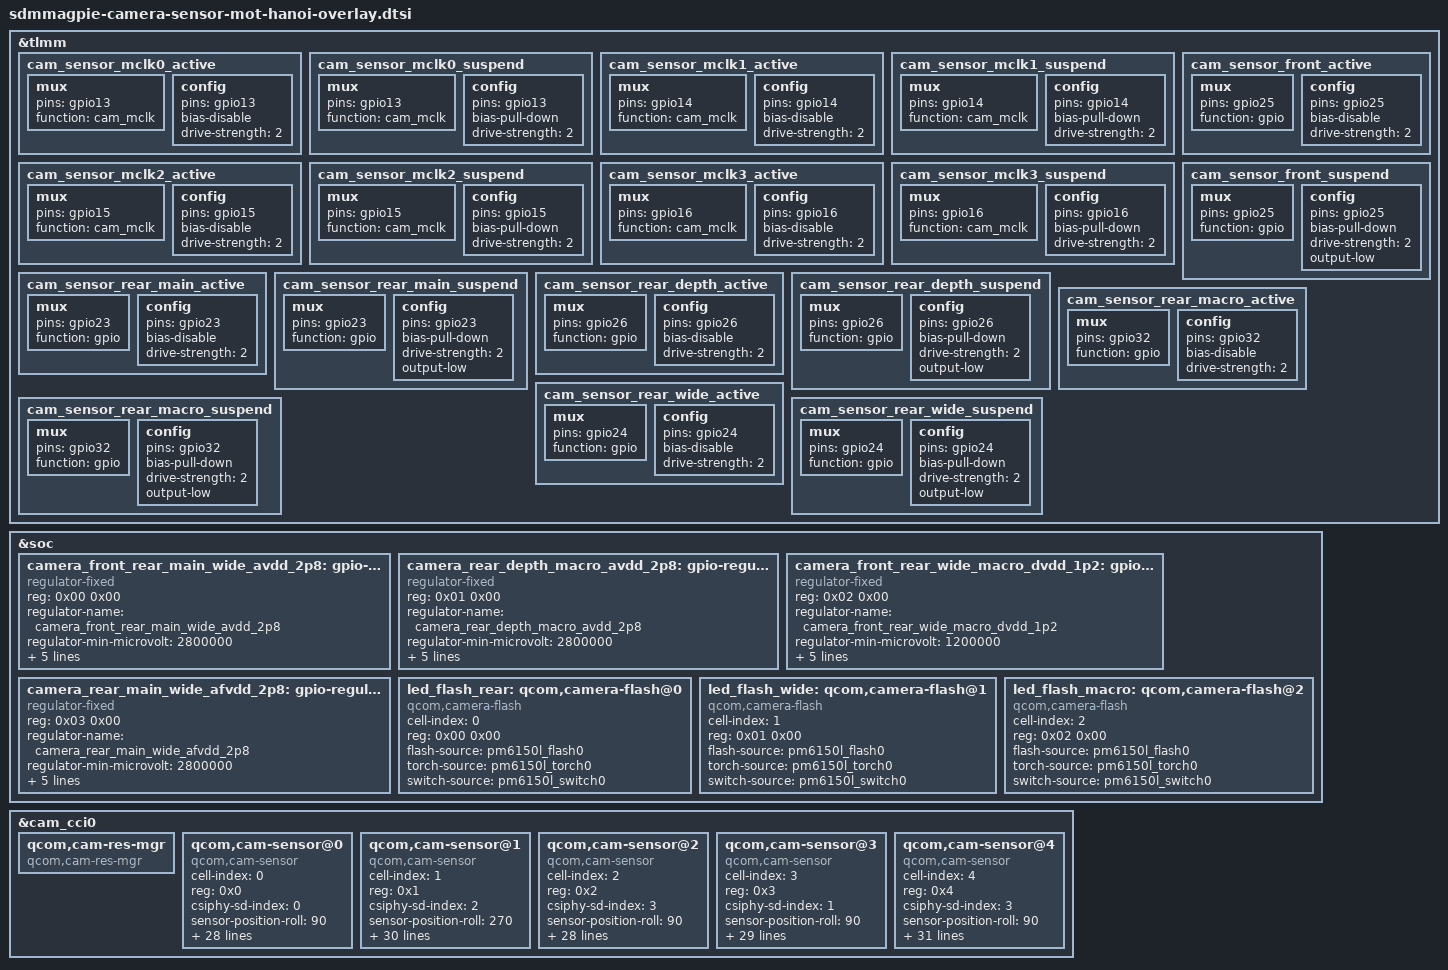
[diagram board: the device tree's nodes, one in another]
/*
 * Copyright (c) 2018-2019, The Linux Foundation. All rights reserved.
 *
 * This program is free software; you can redistribute it and/or modify
 * it under the terms of the GNU General Public License version 2 and
 * only version 2 as published by the Free Software Foundation.
 *
 * This program is distributed in the hope that it will be useful,
 * but WITHOUT ANY WARRANTY; without even the implied warranty of
 * MERCHANTABILITY or FITNESS FOR A PARTICULAR PURPOSE.  See the
 * GNU General Public License for more details.
 */
&tlmm {
/*MCLKs*/
	cam_sensor_mclk0_active: cam_sensor_mclk0_active {
		/* MCLK0 */
		mux {
			pins = "gpio13";
			function = "cam_mclk";
		};

		config {
			pins = "gpio13";
			bias-disable; /* No PULL */
			drive-strength = <2>; /* 2 MA */
		};
	};

	cam_sensor_mclk0_suspend: cam_sensor_mclk0_suspend {
		/* MCLK0 */
		mux {
			pins = "gpio13";
			function = "cam_mclk";
		};

		config {
			pins = "gpio13";
			bias-pull-down; /* PULL DOWN */
			drive-strength = <2>; /* 2 MA */
		};
	};

	cam_sensor_mclk1_active: cam_sensor_mclk1_active {
		/* MCLK1 */
		mux {
			pins = "gpio14";
			function = "cam_mclk";
		};

		config {
			pins = "gpio14";
			bias-disable; /* No PULL */
			drive-strength = <2>; /* 2 MA */
		};
	};

	cam_sensor_mclk1_suspend: cam_sensor_mclk1_suspend {
		/* MCLK1 */
		mux {
			pins = "gpio14";
			function = "cam_mclk";
		};

		config {
			pins = "gpio14";
			bias-pull-down; /* PULL DOWN */
			drive-strength = <2>; /* 2 MA */
		};
	};

	cam_sensor_mclk2_active: cam_sensor_mclk2_active {
		/* MCLK2 */
		mux {
			pins = "gpio15";
			function = "cam_mclk";
		};

		config {
			pins = "gpio15";
			bias-disable; /* No PULL */
			drive-strength = <2>; /* 2 MA */
		};
	};

	cam_sensor_mclk2_suspend: cam_sensor_mclk2_suspend {
		/* MCLK2 */
		mux {
			pins = "gpio15";
			function = "cam_mclk";
		};

		config {
			pins = "gpio15";
			bias-pull-down; /* PULL DOWN */
			drive-strength = <2>; /* 2 MA */
		};
	};

	cam_sensor_mclk3_active: cam_sensor_mclk3_active {
		/* MCLK3 */
		mux {
			pins = "gpio16";
			function = "cam_mclk";
		};

		config {
			pins = "gpio16";
			bias-disable; /* No PULL */
			drive-strength = <2>; /* 2 MA */
		};
	};

	cam_sensor_mclk3_suspend: cam_sensor_mclk3_suspend {
		/* MCLK3 */
		mux {
			pins = "gpio16";
			function = "cam_mclk";
		};

		config {
			pins = "gpio16";
			bias-pull-down; /* PULL DOWN */
			drive-strength = <2>; /* 2 MA */
		};
	};
/*RESETs*/
	cam_sensor_front_active: cam_sensor_front_active {
		/* CAM2_RST  */
		mux {
			pins = "gpio25";
			function = "gpio";
		};

		config {
			pins = "gpio25";
			bias-disable; /* No PULL */
			drive-strength = <2>; /* 2 MA */
		};
	};

	cam_sensor_front_suspend: cam_sensor_front_suspend {
		/* CAM2_RST */
		mux {
			pins = "gpio25";
			function = "gpio";
		};

		config {
			pins = "gpio25";
			bias-pull-down; /* PULL DOWN */
			drive-strength = <2>; /* 2 MA */
			output-low;
		};
	};

	cam_sensor_rear_main_active: cam_sensor_rear_main_active {
		/* CAM0_RST  */
		mux {
			pins = "gpio23";
			function = "gpio";
		};

		config {
			pins = "gpio23";
			bias-disable; /* No PULL */
			drive-strength = <2>; /* 2 MA */
		};
	};

	cam_sensor_rear_main_suspend: cam_sensor_rear_main_suspend {
		/* CAM0_RST */
		mux {
			pins = "gpio23";
			function = "gpio";
		};

		config {
			pins = "gpio23";
			bias-pull-down; /* PULL DOWN */
			drive-strength = <2>; /* 2 MA */
			output-low;
		};
	};

	cam_sensor_rear_depth_active: cam_sensor_rear_depth_active {
		/* CAM3_RST  */
		mux {
			pins = "gpio26";
			function = "gpio";
		};

		config {
			pins = "gpio26";
			bias-disable; /* No PULL */
			drive-strength = <2>; /* 2 MA */
		};
	};

	cam_sensor_rear_depth_suspend: cam_sensor_rear_depth_suspend {
		/* CAM3_RST */
		mux {
			pins = "gpio26";
			function = "gpio";
		};

		config {
			pins = "gpio26";
			bias-pull-down; /* PULL DOWN */
			drive-strength = <2>; /* 2 MA */
			output-low;
		};
	};

	cam_sensor_rear_macro_active: cam_sensor_rear_macro_active {
		/* CAM4_RST  */
		mux {
			pins = "gpio32";
			function = "gpio";
		};

		config {
			pins = "gpio32";
			bias-disable; /* No PULL */
			drive-strength = <2>; /* 2 MA */
		};
	};

	cam_sensor_rear_macro_suspend: cam_sensor_rear_macro_suspend {
		/* CAM4_RST */
		mux {
			pins = "gpio32";
			function = "gpio";
		};

		config {
			pins = "gpio32";
			bias-pull-down; /* PULL DOWN */
			drive-strength = <2>; /* 2 MA */
			output-low;
		};
	};

	cam_sensor_rear_wide_active: cam_sensor_rear_wide_active {
		/* CAM1_RST  */
		mux {
			pins = "gpio24";
			function = "gpio";
		};

		config {
			pins = "gpio24";
			bias-disable; /* No PULL */
			drive-strength = <2>; /* 2 MA */
		};
	};

	cam_sensor_rear_wide_suspend: cam_sensor_rear_wide_suspend {
		/* CAM1_RST */
		mux {
			pins = "gpio24";
			function = "gpio";
		};

		config {
			pins = "gpio24";
			bias-pull-down; /* PULL DOWN */
			drive-strength = <2>; /* 2 MA */
			output-low;
		};
	};
};

&soc {
/*regulators*/
	camera_front_rear_main_wide_avdd_2p8: gpio-regulator@0 {
		/* REAR_CAM_AVDD_2P8*/
		compatible = "regulator-fixed";
		reg = <0x00 0x00>;
		regulator-name = "camera_front_rear_main_wide_avdd_2p8";
		regulator-min-microvolt = <2800000>;
		regulator-max-microvolt = <2800000>;
		regulator-enable-ramp-delay = <233>;
		enable-active-high;
		gpio = <&tlmm 65 0>; /* CAM_R_AVDD_EN*/
		vin-supply = <&pm6150l_bob>; /* VREG_BOB*/
	};

	camera_rear_depth_macro_avdd_2p8: gpio-regulator@1 {
		/* SLAVE_CAM_AVDD_2P8*/
		compatible = "regulator-fixed";
		reg = <0x01 0x00>;
		regulator-name = "camera_rear_depth_macro_avdd_2p8";
		regulator-min-microvolt = <2800000>;
		regulator-max-microvolt = <2800000>;
		regulator-enable-ramp-delay = <233>;
		enable-active-high;
		gpio = <&tlmm 46 0>; /* CAM_S_AVDD_EN*/
		vin-supply = <&pm6150l_bob>; /* VREG_BOB*/
	};

	camera_front_rear_wide_macro_dvdd_1p2: gpio-regulator@2 {
		/* CAM_1P2_DVDD*/
		compatible = "regulator-fixed";
		reg = <0x02 0x00>;
		regulator-name = "camera_front_rear_wide_macro_dvdd_1p2";
		regulator-min-microvolt = <1200000>;
		regulator-max-microvolt = <1200000>;
		regulator-enable-ramp-delay = <233>;
		enable-active-high;
		gpio = <&tlmm 33 0>; /* CAM_S_DVDD_EN*/
		vin-supply = <&pm6150l_s8>; /* VREG_S8C_1P35*/ /*bias: VREG_BOB*/
	};

	camera_rear_main_wide_afvdd_2p8: gpio-regulator@3 {
		/*CAM_AFVCC_2P8*/
		compatible = "regulator-fixed";
		reg = <0x03 0x00>;
		regulator-name = "camera_rear_main_wide_afvdd_2p8";
		regulator-min-microvolt = <2800000>;
		regulator-max-microvolt = <2800000>;
		regulator-enable-ramp-delay = <233>;
		enable-active-high;
		gpio = <&tlmm 64 0>; /* CAM_R_AFVDD_EN*/
		vin-supply = <&pm6150l_bob>; /*VREG_BOB*/
	};

	led_flash_rear: qcom,camera-flash@0 {
		cell-index = <0>;
		reg = <0x00 0x00>;
		compatible = "qcom,camera-flash";
		flash-source = <&pm6150l_flash0>;
		torch-source = <&pm6150l_torch0>;
		switch-source = <&pm6150l_switch0>;
		status = "ok";
	};

	led_flash_wide: qcom,camera-flash@1 {
		cell-index = <1>;
		reg = <0x01 0x00>;
		compatible = "qcom,camera-flash";
		flash-source = <&pm6150l_flash0>;
		torch-source = <&pm6150l_torch0>;
		switch-source = <&pm6150l_switch0>;
		status = "ok";
	};


	led_flash_macro: qcom,camera-flash@2 {
		cell-index = <2>;
		reg = <0x02 0x00>;
		compatible = "qcom,camera-flash";
		flash-source = <&pm6150l_flash0>;
		torch-source = <&pm6150l_torch0>;
		switch-source = <&pm6150l_switch0>;
		status = "ok";
	};

};

&cam_cci0 {
	qcom,cam-res-mgr {
		compatible = "qcom,cam-res-mgr";
		status = "ok";
	};

	qcom,cam-sensor@0 {
		/*rear main ov64b*/
		cell-index = <0>;
		compatible = "qcom,cam-sensor";
		reg = <0x0>;
		csiphy-sd-index = <0>;
		sensor-position-roll = <90>;
		sensor-position-pitch = <0>;
		sensor-position-yaw = <180>;
		cam_vio-supply = <&pm6150_l13>;
		cam_vana-supply = <&camera_front_rear_main_wide_avdd_2p8>;
		cam_vdig-supply = <&pm6150_l6>;
		cam_clk-supply = <&titan_top_gdsc>;
		regulator-names = "cam_vio", "cam_vana", "cam_vdig", "cam_clk";
		rgltr-cntrl-support;
		rgltr-min-voltage = <1800000 2800000 1100000 0>;
		rgltr-max-voltage = <1800000 2800000 1100000 0>;
		rgltr-load-current = <0 80000 105000 0>;
		gpio-no-mux = <0>;
		pinctrl-names = "cam_default", "cam_suspend";
		pinctrl-0 = <&cam_sensor_mclk0_active
				&cam_sensor_rear_main_active>;
		pinctrl-1 = <&cam_sensor_mclk0_suspend
				&cam_sensor_rear_main_suspend>;
		gpios = <&tlmm 13 0>,
			<&tlmm 23 0>;
		gpio-reset = <1>;
		gpio-req-tbl-num = <0 1>;
		gpio-req-tbl-flags = <1 0>;
		gpio-req-tbl-label = "CAMIF_MCLK0", "CAM_RESET0";
		cci-device = <0>;
		cci-master = <0>;
		status = "ok";
		clocks = <&clock_camcc CAM_CC_MCLK0_CLK>;
		clock-names = "cam_clk";
		clock-cntl-level = "turbo";
		clock-rates = <24000000>;
	};

	qcom,cam-sensor@1 {
		/*front ov16a1q*/
		cell-index = <1>;
		compatible = "qcom,cam-sensor";
		reg = <0x1>;
		csiphy-sd-index = <2>;
		sensor-position-roll = <270>;
		sensor-position-pitch = <0>;
		sensor-position-yaw = <0>;
		cam_vio-supply = <&pm6150_l13>;
		cam_vana-supply = <&camera_front_rear_main_wide_avdd_2p8>;
		cam_vdig-supply = <&camera_front_rear_wide_macro_dvdd_1p2>;
		cam_clk-supply = <&titan_top_gdsc>;
		regulator-names = "cam_vio", "cam_vana", "cam_vdig", "cam_clk";
		rgltr-cntrl-support;
		rgltr-min-voltage = <1800000 2800000 1200000 0>;
		rgltr-max-voltage = <1800000 2800000 1200000 0>;
		rgltr-load-current = <0 80000 105000 0>;
		gpio-no-mux = <0>;
		pinctrl-names = "cam_default", "cam_suspend";
		pinctrl-0 = <&cam_sensor_mclk2_active
				&cam_sensor_front_active>;
		pinctrl-1 = <&cam_sensor_mclk2_suspend
				&cam_sensor_front_suspend>;
		gpios = <&tlmm 15 0>,
			<&tlmm 25 0>;
		gpio-reset = <1>;
		gpio-req-tbl-num = <0 1>;
		gpio-req-tbl-flags = <1 0>;
		gpio-req-tbl-label = "CAMIF_MCLK2", "CAM_RESET2";
		sensor-mode = <1>;
		cci-device = <0>;
		cci-master = <0>;
		status = "ok";
		clocks = <&clock_camcc CAM_CC_MCLK2_CLK>;
		clock-names = "cam_clk";
		clock-cntl-level = "turbo";
		clock-rates = <24000000>;
	};

	qcom,cam-sensor@2 {
		/*rear depth ov02b1b*/
		cell-index = <2>;
		compatible = "qcom,cam-sensor";
		reg = <0x2>;
		csiphy-sd-index = <3>;
		sensor-position-roll = <90>;
		sensor-position-pitch = <0>;
		sensor-position-yaw = <180>;
		cam_vio-supply = <&pm6150_l13>;
		cam_vana-supply = <&camera_rear_depth_macro_avdd_2p8>;
		cam_clk-supply = <&titan_top_gdsc>;
		regulator-names = "cam_vio", "cam_vana", "cam_clk";
		rgltr-cntrl-support;
		rgltr-min-voltage = <1800000 2800000 0>;
		rgltr-max-voltage = <1800000 2800000 0>;
		rgltr-load-current = <0 80000 0>;
		gpio-no-mux = <0>;
		pinctrl-names = "cam_default", "cam_suspend";
		pinctrl-0 = <&cam_sensor_mclk3_active
				&cam_sensor_rear_depth_active>;
		pinctrl-1 = <&cam_sensor_mclk3_suspend
				&cam_sensor_rear_depth_suspend>;
		gpios = <&tlmm 16 0>,
			<&tlmm 26 0>,
			<&tlmm 42 0>; /*MIPI_SEL=0 for depth*/
		gpio-reset = <1>;
		gpio-custom1 = <2>;
		gpio-req-tbl-num = <0 1 2>;
		gpio-req-tbl-flags = <1 0 0>;
		gpio-req-tbl-label = "CAMIF_MCLK3", "CAM_RESET3", "CAM_MIPI_SEL";
		cci-device = <0>;
		cci-master = <1>;
		status = "ok";
		clocks = <&clock_camcc CAM_CC_MCLK3_CLK>;
		clock-names = "cam_clk";
		clock-cntl-level = "turbo";
		clock-rates = <24000000>;
	};

	qcom,cam-sensor@3 {
		/*rear wide s5k4h7*/
		cell-index = <3>;
		compatible = "qcom,cam-sensor";
		reg = <0x3>;
		csiphy-sd-index = <1>;
		sensor-position-roll = <90>;
		sensor-position-pitch = <0>;
		sensor-position-yaw = <180>;
		cam_vio-supply = <&pm6150_l13>;
		cam_vana-supply = <&camera_front_rear_main_wide_avdd_2p8>;
		cam_vdig-supply = <&camera_front_rear_wide_macro_dvdd_1p2>;
		cam_clk-supply = <&titan_top_gdsc>;
		regulator-names = "cam_vio", "cam_vana", "cam_vdig", "cam_clk";
		rgltr-cntrl-support;
		rgltr-min-voltage = <1800000 2800000 1200000 0>;
		rgltr-max-voltage = <1800000 2800000 1200000 0>;
		rgltr-load-current = <0 80000 105000 0>;
		gpio-no-mux = <0>;
		pinctrl-names = "cam_default", "cam_suspend";
		pinctrl-0 = <&cam_sensor_mclk1_active
				&cam_sensor_rear_wide_active>;
		pinctrl-1 = <&cam_sensor_mclk1_suspend
				&cam_sensor_rear_wide_suspend>;
		gpios = <&tlmm 14 0>,
			<&tlmm 24 0>;
		gpio-reset = <1>;
		gpio-req-tbl-num = <0 1>;
		gpio-req-tbl-flags = <1 0>;
		gpio-req-tbl-label = "CAMIF_MCLK1", "CAM_RESET1";
		cci-device = <0>;
		cci-master = <1>;
		status = "ok";
		clocks = <&clock_camcc CAM_CC_MCLK1_CLK>;
		clock-names = "cam_clk";
		clock-cntl-level = "turbo";
		clock-rates = <24000000>;
	};

	qcom,cam-sensor@4 {
		/*rear macro s5k5e9*/
		cell-index = <4>;
		compatible = "qcom,cam-sensor";
		reg = <0x4>;
		csiphy-sd-index = <3>;
		sensor-position-roll = <90>;
		sensor-position-pitch = <0>;
		sensor-position-yaw = <180>;
		cam_vio-supply = <&pm6150_l13>;
		cam_vana-supply = <&camera_rear_depth_macro_avdd_2p8>;
		cam_vdig-supply = <&camera_front_rear_wide_macro_dvdd_1p2>;
		cam_clk-supply = <&titan_top_gdsc>;
		regulator-names = "cam_vio", "cam_vana", "cam_vdig", "cam_clk";
		rgltr-cntrl-support;
		rgltr-min-voltage = <1800000 2800000 1200000 0>;
		rgltr-max-voltage = <1800000 2800000 1200000 0>;
		rgltr-load-current = <0 80000 105000 0>;
		gpio-no-mux = <0>;
		pinctrl-names = "cam_default", "cam_suspend";
		pinctrl-0 = <&cam_sensor_mclk3_active
				&cam_sensor_rear_macro_active>;
		pinctrl-1 = <&cam_sensor_mclk3_suspend
				&cam_sensor_rear_macro_suspend>;
		gpios = <&tlmm 16 0>,
			<&tlmm 32 0>,
			<&tlmm 42 0>; /*MIPI_SEL=1 for macro*/
		gpio-reset = <1>;
		gpio-custom1= <2>;
		gpio-req-tbl-num = <0 1 2>;
		gpio-req-tbl-flags = <1 0 0>;
		gpio-req-tbl-label = "CAMIF_MCLK3", "CAM_RESET4", "CAM_MIPI_SEL";
		cci-device = <0>;
		cci-master = <1>;
		status = "ok";
		clocks = <&clock_camcc CAM_CC_MCLK3_CLK>;
		clock-names = "cam_clk";
		clock-cntl-level = "turbo";
		clock-rates = <24000000>;
	};
};

